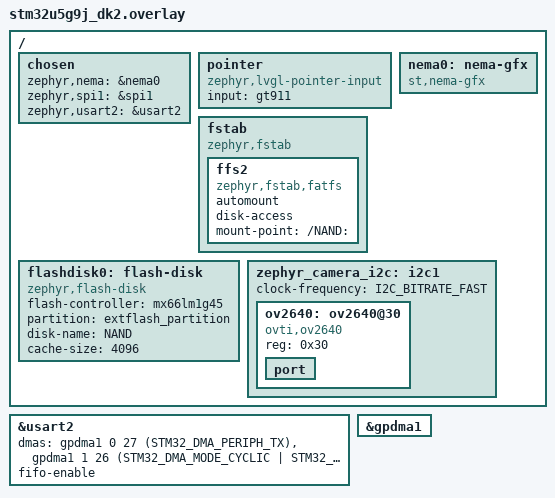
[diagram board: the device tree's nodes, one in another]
/*
 * Copyright (c) 2024, Eve Redero
 *
 * SPDX-License-Identifier: Apache-2.0
 */

#include <zephyr/dt-bindings/input/input-event-codes.h>
#include <zephyr/dt-bindings/lvgl/lvgl.h>

/ {
	chosen: chosen {
		zephyr,nema = &nema0;
		zephyr,spi1 = &spi1;
		zephyr,usart2 = &usart2;
	};

	pointer {
		compatible = "zephyr,lvgl-pointer-input";
		input = <&gt911>;
	};

	fstab {
		compatible = "zephyr,fstab";

        ffs2: ffs2 {
			compatible = "zephyr,fstab,fatfs";
			automount;
			disk-access;
			mount-point = "/NAND:";
		};
	};

    flashdisk0: flash-disk {
        compatible = "zephyr,flash-disk";
        flash-controller = <&mx66lm1g45>;
        partition = <&extflash_partition>;
        disk-name = "NAND";
        cache-size = <4096>;
    };

	nema0: nema-gfx {
		compatible = "st,nema-gfx";
		status = "okay";
	};

	zephyr_camera_i2c: i2c1 {
		#address-cells = <1>;
	    #size-cells    = <0>;

		status = "okay";
		clock-frequency = <I2C_BITRATE_FAST>;

		ov2640: ov2640@30 {
			compatible = "ovti,ov2640";
			reg = <0x30>;
			status = "okay";

			port {
			};
		};
	};
};

/*
&spi1 {
	clock-frequency = <DT_FREQ_M(2)>;
	
	pinctrl-0 = <&spi1_sck_pa5 &spi1_miso_pa6 &spi1_mosi_pb5>;
	pinctrl-names = "default";
	cs-gpios = <&gpiob 11 (GPIO_ACTIVE_LOW | GPIO_PULL_UP)>;
	status = "okay";
};
*/

&usart2 {
	dmas = <&gpdma1 0 27 (STM32_DMA_PERIPH_TX)
			&gpdma1 1 26 (STM32_DMA_MODE_CYCLIC | STM32_DMA_PERIPH_RX | STM32_DMA_MEM_8BITS)>;
	dma-names = "tx", "rx";
	fifo-enable;
};

&gpdma1 {
	status = "okay";
};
